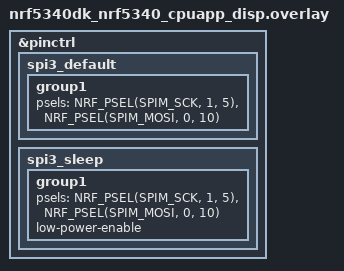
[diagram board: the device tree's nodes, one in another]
/*
 * Display test pin override.
 * Applied on top of nrf5340dk_nrf5340_cpuapp_ns.overlay for the build_disp build.
 *
 * SPI3 MOSI rerouted to former MISO testpoint on P0.10.
 * SCK stays at P1.05.
 */

&pinctrl {
	spi3_default: spi3_default {
		group1 {
			psels = <NRF_PSEL(SPIM_SCK,  1, 5)>,
				<NRF_PSEL(SPIM_MOSI, 0, 10)>;
		};
	};
	spi3_sleep: spi3_sleep {
		group1 {
			psels = <NRF_PSEL(SPIM_SCK,  1, 5)>,
				<NRF_PSEL(SPIM_MOSI, 0, 10)>;
			low-power-enable;
		};
	};
};
